# STM32F412 register map
File version: 1.4
CPU: CM4 r0p1, little endian, MPU, FPU, 4 interrupt priority bits
Registers are 32-bit, read-write, reset 0x0 unless marked. A register's access mark holds for its fields unless they carry their own. Offsets are from the block's base; [hi:lo] are bit positions; {n}, {i} and the like mark numbered series; 'fields as' and 'values as' point back to an identical list.

## SYSCFG — System configuration controller
Base 0x40013800
0x00 MEMRM — memory remap register
  [1:0] MEM_MODE
0x04 PMC — peripheral mode configuration register
  [16] ADC1DC2
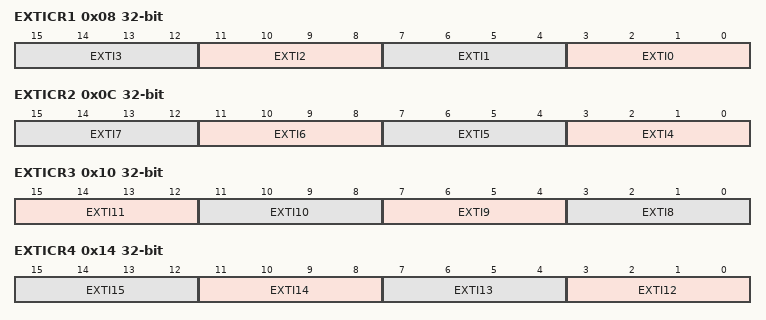
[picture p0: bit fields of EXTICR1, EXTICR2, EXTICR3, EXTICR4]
0x08 EXTICR1 — external interrupt configuration register 1
  [4n+3:4n] EXTI{n} (n=0..3) — EXTI x configuration (x = 0 to 3)
0x0C EXTICR2 — external interrupt configuration register 2
  [4n-13:4n-16] EXTI{n} (n=4..7) — EXTI x configuration (x = 4 to 7)
0x10 EXTICR3 — external interrupt configuration register 3
  [15:12] EXTI11 — EXTI x configuration (x = 8 to 11)
  [11:8] EXTI10
  [7:4] EXTI9 — EXTI x configuration (x = 8 to 11)
  [3:0] EXTI8 — EXTI x configuration (x = 8 to 11)
0x14 EXTICR4 — external interrupt configuration register 4
  [4n-45:4n-48] EXTI{n} (n=12..15) — EXTI x configuration (x = 12 to 15)
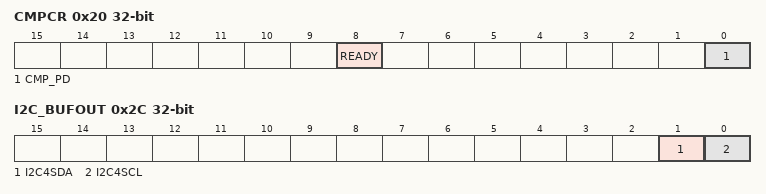
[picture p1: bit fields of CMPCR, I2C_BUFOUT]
0x20 CMPCR ro — Compensation cell control register
  [8] READY
  [0] CMP_PD — Compensation cell power-down
0x2C I2C_BUFOUT
  [1] I2C4SDA, [0] I2C4SCL

## TIM10 — General-purpose-timers
Base 0x40014400
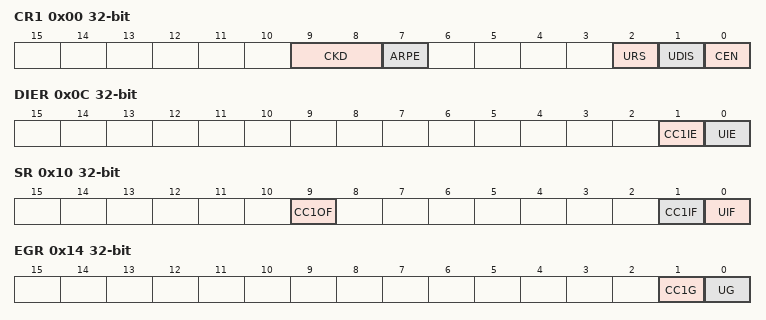
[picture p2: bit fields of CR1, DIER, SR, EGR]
0x00 CR1 — control register 1
  [9:8] CKD — Clock division
  [7] ARPE — Auto-reload preload enable
  [2] URS — Update request source
  [1] UDIS — Update disable
  [0] CEN — Counter enable
0x0C DIER — DMA/Interrupt enable register
  [1] CC1IE — Capture/Compare 1 interrupt enable
  [0] UIE — Update interrupt enable
0x10 SR — status register
  [9] CC1OF — Capture/Compare 1 overcapture flag
  [1] CC1IF — Capture/compare 1 interrupt flag
  [0] UIF — Update interrupt flag
0x14 EGR wo — event generation register
  [1] CC1G — Capture/compare 1 generation
  [0] UG — Update generation
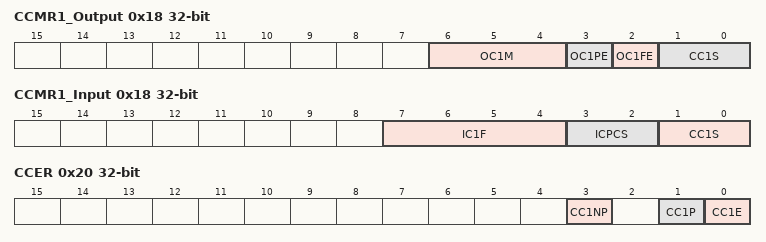
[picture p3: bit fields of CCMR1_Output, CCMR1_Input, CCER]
0x18 CCMR1_Output — capture/compare mode register 1 (output mode)
  [6:4] OC1M — Output Compare 1 mode
  [3] OC1PE — Output Compare 1 preload enable
  [2] OC1FE — Output Compare 1 fast enable
  [1:0] CC1S — Capture/Compare 1 selection
0x18 CCMR1_Input (alternate view of CCMR1_Output) — capture/compare mode register 1 (input mode)
  [7:4] IC1F — Input capture 1 filter
  [3:2] ICPCS — Input capture 1 prescaler
  [1:0] CC1S — Capture/Compare 1 selection
0x20 CCER — capture/compare enable register
  [3] CC1NP — Capture/Compare 1 output Polarity
  [1] CC1P — Capture/Compare 1 output Polarity
  [0] CC1E — Capture/Compare 1 output enable
0x24 CNT — counter
  [15:0] CNT — counter value
0x28 PSC — prescaler
  [15:0] PSC — Prescaler value
0x2C ARR — auto-reload register
  [15:0] ARR — Auto-reload value
0x34 CCR1 — capture/compare register 1
  [15:0] CCR1 — Capture/Compare 1 value

## TIM11 — General-purpose-timers
Base 0x40014800
Registers as TIM10; these are added or differ:
0x50 OR — option register
  [1:0] RMP — Input 1 remapping capability

## TIM13 — General purpose timers
Base 0x40001C00
Same registers: TIM14 0x40002000
Registers as TIM10; these are added or differ:
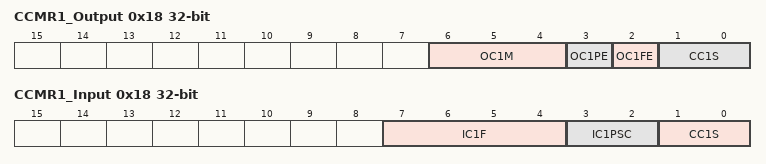
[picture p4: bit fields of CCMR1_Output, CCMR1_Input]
0x18 CCMR1_Output — capture/compare mode register (output mode)
  [6:4] OC1M — Output Compare 1 mode
  [3] OC1PE — Output Compare 1 preload enable
  [2] OC1FE — Output compare 1 fast enable
  [1:0] CC1S — Capture/Compare 1 selection
0x18 CCMR1_Input (alternate view of CCMR1_Output) — capture/compare mode register (input mode)
  [7:4] IC1F — Input capture 1 filter
  [3:2] IC1PSC — Input capture 1 prescaler
  [1:0] CC1S — Capture/Compare 1 selection

## TIM9 — General purpose timers
Base 0x40014000
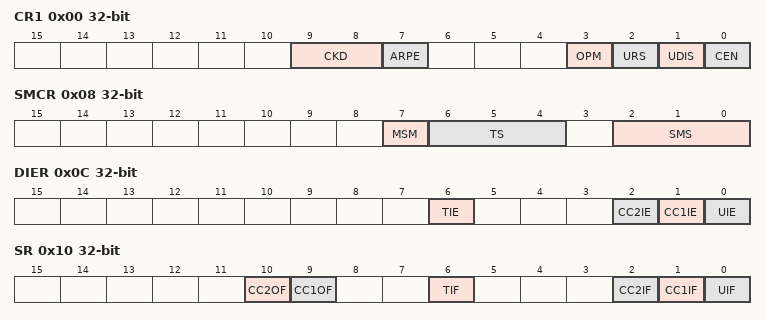
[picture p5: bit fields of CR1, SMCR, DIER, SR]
0x00 CR1 — control register 1
  [9:8] CKD — Clock division
  [7] ARPE — Auto-reload preload enable
  [3] OPM — One-pulse mode
  [2] URS — Update request source
  [1] UDIS — Update disable
  [0] CEN — Counter enable
0x04 CR2 — control register 2
  [6:4] MMS — Master mode selection
0x08 SMCR — slave mode control register
  [7] MSM — Master/Slave mode
  [6:4] TS — Trigger selection
  [2:0] SMS — Slave mode selection
0x0C DIER — DMA/Interrupt enable register
  [6] TIE — Trigger interrupt enable
  [2] CC2IE — Capture/Compare 2 interrupt enable
  [1] CC1IE — Capture/Compare 1 interrupt enable
  [0] UIE — Update interrupt enable
0x10 SR — status register
  [10] CC2OF — Capture/compare 2 overcapture flag
  [9] CC1OF — Capture/Compare 1 overcapture flag
  [6] TIF — Trigger interrupt flag
  [2] CC2IF — Capture/Compare 2 interrupt flag
  [1] CC1IF — Capture/compare 1 interrupt flag
  [0] UIF — Update interrupt flag
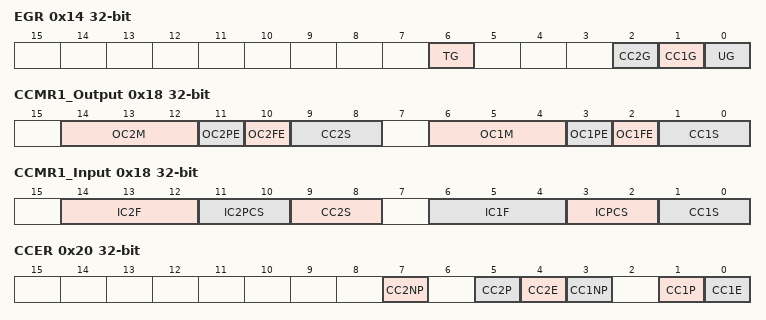
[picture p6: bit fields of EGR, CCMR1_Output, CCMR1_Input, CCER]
0x14 EGR wo — event generation register
  [6] TG — Trigger generation
  [2] CC2G — Capture/compare 2 generation
  [1] CC1G — Capture/compare 1 generation
  [0] UG — Update generation
0x18 CCMR1_Output — capture/compare mode register 1 (output mode)
  [14:12] OC2M — Output Compare 2 mode
  [11] OC2PE — Output Compare 2 preload enable
  [10] OC2FE — Output Compare 2 fast enable
  [9:8] CC2S — Capture/Compare 2 selection
  [6:4] OC1M — Output Compare 1 mode
  [3] OC1PE — Output Compare 1 preload enable
  [2] OC1FE — Output Compare 1 fast enable
  [1:0] CC1S — Capture/Compare 1 selection
0x18 CCMR1_Input (alternate view of CCMR1_Output) — capture/compare mode register 1 (input mode)
  [14:12] IC2F — Input capture 2 filter
  [11:10] IC2PCS — Input capture 2 prescaler
  [9:8] CC2S — Capture/Compare 2 selection
  [6:4] IC1F — Input capture 1 filter
  [3:2] ICPCS — Input capture 1 prescaler
  [1:0] CC1S — Capture/Compare 1 selection
0x20 CCER — capture/compare enable register
  [7] CC2NP — Capture/Compare 2 output Polarity
  [5] CC2P — Capture/Compare 2 output Polarity
  [4] CC2E — Capture/Compare 2 output enable
  [3] CC1NP — Capture/Compare 1 output Polarity
  [1] CC1P — Capture/Compare 1 output Polarity
  [0] CC1E — Capture/Compare 1 output enable
0x24 CNT — counter
  [15:0] CNT — counter value
0x28 PSC — prescaler
  [15:0] PSC — Prescaler value
0x2C ARR — auto-reload register
  [15:0] ARR — Auto-reload value
0x34 CCR1 — capture/compare register 1
  [15:0] CCR1 — Capture/Compare 1 value
0x38 CCR2 — capture/compare register 2
  [15:0] CCR2 — Capture/Compare 2 value

## TIM12 — General purpose timers
Base 0x40001800
Registers as TIM9, without CR2; these are added or differ:
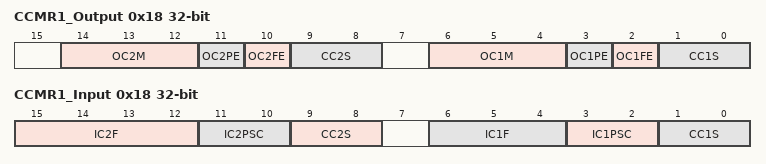
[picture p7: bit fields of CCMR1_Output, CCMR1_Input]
0x18 CCMR1_Output — capture/compare mode register (output mode)
  fields as TIM9.CCMR1_Output
0x18 CCMR1_Input (alternate view of CCMR1_Output) — capture/compare mode register 1 (input mode)
  [15:12] IC2F — Input capture 2 filter
  [11:10] IC2PSC — Input capture 2 prescaler
  [9:8] CC2S — Capture/Compare 2 selection
  [6:4] IC1F — Input capture 1 filter
  [3:2] IC1PSC — Input capture 1 prescaler
  [1:0] CC1S — Capture/Compare 1 selection
